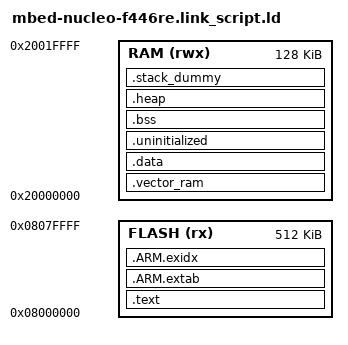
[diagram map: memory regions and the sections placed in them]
M_CRASH_DATA_RAM_SIZE = 0x100;
STACK_SIZE = 0x400;
MEMORY
{
    FLASH (rx) : ORIGIN = 0x8000000, LENGTH = 0x80000
    RAM (rwx) : ORIGIN = 0x20000000, LENGTH = 0x20000
}
ENTRY(Reset_Handler)
SECTIONS
{
    .text :
    {
        __vector_flash_start__ = ABSOLUTE(.);
        KEEP(*(.isr_vector))
        __vector_flash_end__ = ABSOLUTE(.);
        __vector_table_size__ = ABSOLUTE(__vector_flash_end__ - __vector_flash_start__);
        *(.text*)
        KEEP(*(.init))
        KEEP(*(.fini))
        *crtbegin.o(.ctors)
        *crtbegin?.o(.ctors)
        *(EXCLUDE_FILE(*crtend?.o *crtend.o) .ctors)
        *(SORT(.ctors.*))
        *(.ctors)
        *crtbegin.o(.dtors)
        *crtbegin?.o(.dtors)
        *(EXCLUDE_FILE(*crtend?.o *crtend.o) .dtors)
        *(SORT(.dtors.*))
        *(.dtors)
        *(.rodata*)
        KEEP(*(.eh_frame*))
    } > FLASH
    .ARM.extab :
    {
        *(.ARM.extab* .gnu.linkonce.armextab.*)
    } > FLASH
    __exidx_start = .;
    .ARM.exidx :
    {
        *(.ARM.exidx* .gnu.linkonce.armexidx.*)
    } > FLASH
    __exidx_end = .;
    __etext = .;
    _sidata = .;
    .vector_ram (NOLOAD) :
    {
        __vector_ram_start__ = .;
        . += __vector_table_size__;
        __vector_ram_end__ = .;
    } > RAM
    .data : AT (__etext)
    {
        __data_start__ = .;
        _sdata = .;
        *(vtable)
        *(.data*)
        . = ALIGN(8);
        PROVIDE_HIDDEN (__preinit_array_start = .);
        KEEP(*(.preinit_array))
        PROVIDE_HIDDEN (__preinit_array_end = .);
        . = ALIGN(8);
        PROVIDE_HIDDEN (__init_array_start = .);
        KEEP(*(SORT(.init_array.*)))
        KEEP(*(.init_array))
        PROVIDE_HIDDEN (__init_array_end = .);
        . = ALIGN(8);
        PROVIDE_HIDDEN (__fini_array_start = .);
        KEEP(*(SORT(.fini_array.*)))
        KEEP(*(.fini_array))
        PROVIDE_HIDDEN (__fini_array_end = .);
        KEEP(*(.jcr*))
        . = ALIGN(8);
        __data_end__ = .;
        _edata = .;
    } > RAM
    .uninitialized (NOLOAD):
    {
        . = ALIGN(32);
        __uninitialized_start = .;
        *(.uninitialized)
        KEEP(*(.keep.uninitialized))
        . = ALIGN(32);
        __uninitialized_end = .;
    } > RAM
    .bss :
    {
        . = ALIGN(8);
        __bss_start__ = .;
        _sbss = .;
        *(.bss*)
        *(COMMON)
        . = ALIGN(8);
        __bss_end__ = .;
        _ebss = .;
    } > RAM
    .heap (COPY):
    {
        __end__ = .;
        PROVIDE(end = .);
        *(.heap*)
        . = ORIGIN(RAM) + LENGTH(RAM) - STACK_SIZE;
        __HeapLimit = .;
    } > RAM
    .stack_dummy (COPY):
    {
        *(.stack*)
    } > RAM
    __StackTop = ORIGIN(RAM) + LENGTH(RAM);
    _estack = __StackTop;
    __StackLimit = __StackTop - STACK_SIZE;
    PROVIDE(__stack = __StackTop);
    ASSERT(__StackLimit >= __HeapLimit, "region RAM overflowed with stack")
}
